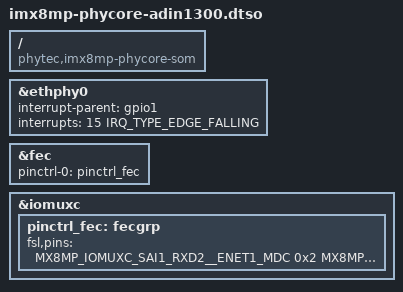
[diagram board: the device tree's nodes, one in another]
// SPDX-License-Identifier: GPL-2.0
/*
 * Copyright (C) 2022 PHYTEC Messtechnik GmbH
 *
 * phyCORE-i.MX8MP PMA-024 mapper support for alternativ ethernet
 * phy ADIN1300.
 *
 */

/dts-v1/;
/plugin/;

#include <dt-bindings/gpio/gpio.h>
#include <dt-bindings/interrupt-controller/arm-gic.h>

#include "../imx8mp-pinfunc.h"

/ {
	compatible = "phytec,imx8mp-phycore-som";
};

&ethphy0 {
	interrupt-parent = <&gpio1>;
	interrupts = <15 IRQ_TYPE_EDGE_FALLING>;
};

&fec {
	pinctrl-0 = <&pinctrl_fec>;
};

&iomuxc {
	pinctrl_fec: fecgrp {
		fsl,pins = <
			MX8MP_IOMUXC_SAI1_RXD2__ENET1_MDC		0x2
			MX8MP_IOMUXC_SAI1_RXD3__ENET1_MDIO		0x2
			MX8MP_IOMUXC_SAI1_RXD4__ENET1_RGMII_RD0		0x90
			MX8MP_IOMUXC_SAI1_RXD5__ENET1_RGMII_RD1		0x90
			MX8MP_IOMUXC_SAI1_RXD6__ENET1_RGMII_RD2		0x90
			MX8MP_IOMUXC_SAI1_RXD7__ENET1_RGMII_RD3		0x90
			MX8MP_IOMUXC_SAI1_TXC__ENET1_RGMII_RXC		0x90
			MX8MP_IOMUXC_SAI1_TXD0__ENET1_RGMII_TD0		0x14
			MX8MP_IOMUXC_SAI1_TXD1__ENET1_RGMII_TD1		0x14
			MX8MP_IOMUXC_SAI1_TXD2__ENET1_RGMII_TD2		0x14
			MX8MP_IOMUXC_SAI1_TXD3__ENET1_RGMII_TD3		0x14
			MX8MP_IOMUXC_SAI1_TXD4__ENET1_RGMII_TX_CTL	0x14
			MX8MP_IOMUXC_SAI1_TXD5__ENET1_RGMII_TXC		0x14
			MX8MP_IOMUXC_SAI1_TXFS__ENET1_RGMII_RX_CTL	0x90
			MX8MP_IOMUXC_GPIO1_IO15__GPIO1_IO15		0x10
		>;
	};
};
